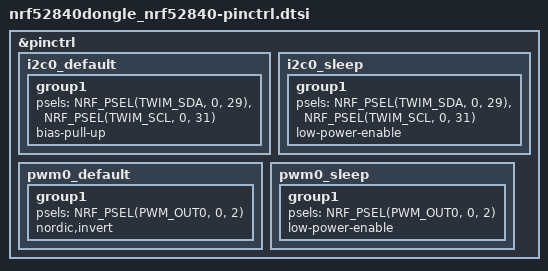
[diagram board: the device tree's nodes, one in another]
// Copyright (c) 2023 Sword Health

&pinctrl {

    i2c0_default: i2c0_default {
        group1 {
            psels = <NRF_PSEL(TWIM_SDA, 0, 29)>,
                    <NRF_PSEL(TWIM_SCL, 0, 31)>;
            bias-pull-up;
        };
    };

    i2c0_sleep: i2c0_sleep {
        group1 {
            psels = <NRF_PSEL(TWIM_SDA, 0, 29)>,
                    <NRF_PSEL(TWIM_SCL, 0, 31)>;
            low-power-enable;
        };
    };

    	pwm0_default: pwm0_default {
		group1 {
			psels = <NRF_PSEL(PWM_OUT0, 0, 2)>;
			nordic,invert;
		};
	};

	pwm0_sleep: pwm0_sleep {
		group1 {
			psels = <NRF_PSEL(PWM_OUT0, 0, 2)>;
			low-power-enable;
		};
	};
  };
